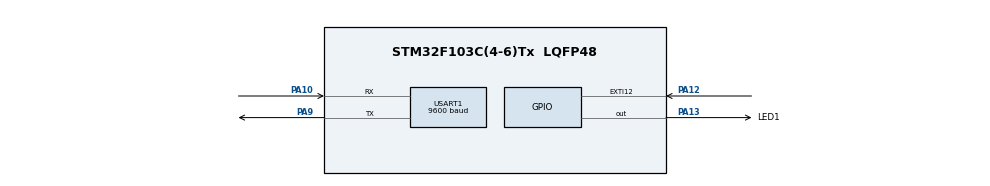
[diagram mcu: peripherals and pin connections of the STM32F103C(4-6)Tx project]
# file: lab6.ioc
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Mcu.Family=STM32F1
Mcu.Name=STM32F103C(4-6)Tx
Mcu.Package=LQFP48
NVIC.EXTI15_10_IRQn=true\:0\:0\:false\:true\:true\:1\:true\:true
NVIC.PriorityGroup=NVIC_PRIORITYGROUP_4
NVIC.USART1_IRQn=true\:0\:0\:false\:false\:true\:true\:true
PA10.Mode=Asynchronous
PA10.Signal=USART1_RX
PA12.Signal=GPXTI12
PA13.GPIO_Label=LED1
PA13.Signal=GPIO_Output
PA9.Mode=Asynchronous
PA9.Signal=USART1_TX
ProjectManager.HeapSize=0x200
ProjectManager.StackSize=0x400
ProjectManager.TargetToolchain=STM32CubeIDE
RCC.APB1Freq_Value=8000000
RCC.APB2Freq_Value=8000000
USART1.BaudRate=9600
USART1.VirtualMode=VM_ASYNC
VP_SYS_VS_ND.Mode=No_Debug
board=custom

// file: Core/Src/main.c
/* USER CODE BEGIN Header */
/**
  ******************************************************************************
  * @file           : main.c
  * @brief          : Main program body
  ******************************************************************************
  * @attention
  *
  * <h2><center>&copy; Copyright (c) 2021 STMicroelectronics.
  * All rights reserved.</center></h2>
  *
  * This software component is licensed by ST under BSD 3-Clause license,
  * the "License"; You may not use this file except in compliance with the
  * License. You may obtain a copy of the License at:
  *                        opensource.org/licenses/BSD-3-Clause
  *
  ******************************************************************************
  */
/* USER CODE END Header */
#include "main.h"

UART_HandleTypeDef huart1;

void SystemClock_Config(void);
static void MX_GPIO_Init(void);
static void MX_USART1_UART_Init(void);
static void MX_NVIC_Init(void);

int main(void)
{

  /* MCU Configuration--------------------------------------------------------*/

  /* Reset of all peripherals, Initializes the Flash interface and the Systick. */
  HAL_Init();

  /* Configure the system clock */
  SystemClock_Config();

  /* Initialize all configured peripherals */
  MX_GPIO_Init();
  MX_USART1_UART_Init();

  /* Initialize interrupts */
  MX_NVIC_Init();

  /* Infinite loop */
  /* USER CODE BEGIN WHILE */
  while (1)
  {
	HAL_UART_Transmit_IT(&huart1, (uint8_t*)"Hello\n\r", sizeof("Hello\n\r"));
    /* USER CODE END WHILE */

  }
}

void SystemClock_Config(void)
{
  RCC_OscInitTypeDef RCC_OscInitStruct = {0};
  RCC_ClkInitTypeDef RCC_ClkInitStruct = {0};

  /** Initializes the RCC Oscillators according to the specified parameters
  * in the RCC_OscInitTypeDef structure.
  */
  RCC_OscInitStruct.OscillatorType = RCC_OSCILLATORTYPE_HSI;
  RCC_OscInitStruct.HSIState = RCC_HSI_ON;
  RCC_OscInitStruct.HSICalibrationValue = RCC_HSICALIBRATION_DEFAULT;
  RCC_OscInitStruct.PLL.PLLState = RCC_PLL_NONE;
  if (HAL_RCC_OscConfig(&RCC_OscInitStruct) != HAL_OK)
  {
    Error_Handler();
  }
  /** Initializes the CPU, AHB and APB buses clocks
  */
  RCC_ClkInitStruct.ClockType = RCC_CLOCKTYPE_HCLK|RCC_CLOCKTYPE_SYSCLK
                              |RCC_CLOCKTYPE_PCLK1|RCC_CLOCKTYPE_PCLK2;
  RCC_ClkInitStruct.SYSCLKSource = RCC_SYSCLKSOURCE_HSI;
  RCC_ClkInitStruct.AHBCLKDivider = RCC_SYSCLK_DIV1;
  RCC_ClkInitStruct.APB1CLKDivider = RCC_HCLK_DIV1;
  RCC_ClkInitStruct.APB2CLKDivider = RCC_HCLK_DIV1;

  if (HAL_RCC_ClockConfig(&RCC_ClkInitStruct, FLASH_LATENCY_0) != HAL_OK)
  {
    Error_Handler();
  }
}

/**
  * @brief NVIC Configuration.
  * @retval None
  */
static void MX_NVIC_Init(void)
{
  /* EXTI15_10_IRQn interrupt configuration */
  HAL_NVIC_SetPriority(EXTI15_10_IRQn, 0, 0);
  HAL_NVIC_EnableIRQ(EXTI15_10_IRQn);
}

static void MX_USART1_UART_Init(void)
{

  huart1.Instance = USART1;
  huart1.Init.BaudRate = 9600;
  huart1.Init.WordLength = UART_WORDLENGTH_8B;
  huart1.Init.StopBits = UART_STOPBITS_1;
  huart1.Init.Parity = UART_PARITY_NONE;
  huart1.Init.Mode = UART_MODE_TX_RX;
  huart1.Init.HwFlowCtl = UART_HWCONTROL_NONE;
  huart1.Init.OverSampling = UART_OVERSAMPLING_16;
  if (HAL_UART_Init(&huart1) != HAL_OK)
  {
    Error_Handler();
  }

}

static void MX_GPIO_Init(void)
{
  GPIO_InitTypeDef GPIO_InitStruct = {0};

  /* GPIO Ports Clock Enable */
  __HAL_RCC_GPIOA_CLK_ENABLE();

  /*Configure GPIO pin Output Level */
  HAL_GPIO_WritePin(LED1_GPIO_Port, LED1_Pin, GPIO_PIN_RESET);

  /*Configure GPIO pin : PA12 */
  GPIO_InitStruct.Pin = GPIO_PIN_12;
  GPIO_InitStruct.Mode = GPIO_MODE_IT_RISING;
  GPIO_InitStruct.Pull = GPIO_NOPULL;
  HAL_GPIO_Init(GPIOA, &GPIO_InitStruct);

  /*Configure GPIO pin : LED1_Pin */
  GPIO_InitStruct.Pin = LED1_Pin;
  GPIO_InitStruct.Mode = GPIO_MODE_OUTPUT_PP;
  GPIO_InitStruct.Pull = GPIO_NOPULL;
  GPIO_InitStruct.Speed = GPIO_SPEED_FREQ_LOW;
  HAL_GPIO_Init(LED1_GPIO_Port, &GPIO_InitStruct);

}

/* USER CODE BEGIN 4 */
int num = 0;

void HAL_GPIO_EXTI_Callback(uint16_t GPIO_Pin){
	num = 0;
	HAL_GPIO_TogglePin(LED1_GPIO_Port, LED1_Pin);
}

void HAL_UART_TxCpltCallback(UART_HandleTypeDef *huart)
{
	char string1[3];
	itoa(++num, string1, 10);

	HAL_UART_Transmit(&huart1, (uint8_t*)"\n\rHello world ", sizeof("\n\rHello world "), 10000);
	HAL_UART_Transmit(&huart1, (uint8_t*)string1, sizeof(string1), 10000);

	char string2[3];
	itoa(++num, string2, 10);

	HAL_UART_Transmit(&huart1, (uint8_t*)"\n\rHello students ", sizeof("\n\rHello students "), 10000);
	HAL_UART_Transmit_IT(&huart1, (uint8_t*)string2, sizeof(string2));
}

/* USER CODE END 4 */

void Error_Handler(void)
{
  __disable_irq();
  while (1)
  {
  }
}

/************************ (C) COPYRIGHT STMicroelectronics *****END OF FILE****/
